# AM13E230x register map
Vendor: Texas Instruments; File version: Revised: 2025-12-26 17:30:06
CPU: CM33 r0p0, little endian, MPU, FPU, 4 interrupt priority bits
Registers are 32-bit, read-write, reset 0x0 unless marked. A register's access mark holds for its fields unless they carry their own. Offsets are from the block's base; [hi:lo] are bit positions; {n}, {i} and the like mark numbered series; 'fields as' and 'values as' point back to an identical list.

## GSC — GSC_LITE_INTERNAL_REGS
Base 0x40046000
0x1004 SPC_ATTRIBVIOLP_CONFIG — SRAM Privilege Access Attribute Violation Configuration Register
  [0] PRIVVIOL — Privilege access to non-privilege SRAM
0x1014 PPC_ATTRIBVIOLP_CONFIG — Peripheral Privilege Access Attribute Violation Configuration Register
  [0] PRIVVIOL — Privilege access to non-privilege Peripheral
0x1024 FPC_ATTRIBVIOLP_CONFIG — Flash Privilege Access Attribute Violation Configuration Register
  [0] PRIVVIOL — Privilege access to non-privilege Flash
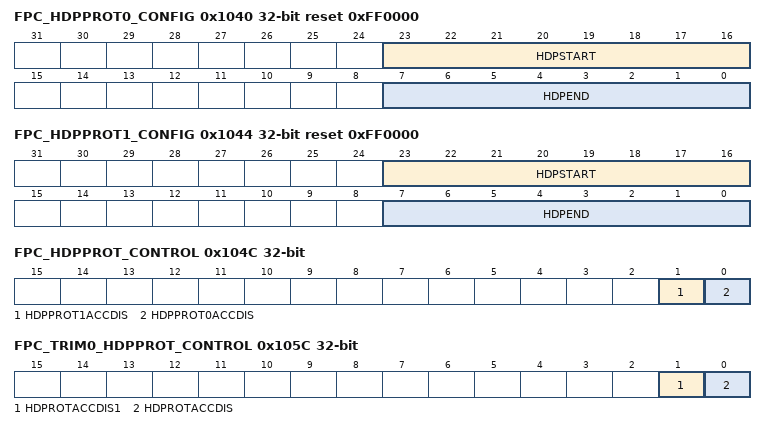
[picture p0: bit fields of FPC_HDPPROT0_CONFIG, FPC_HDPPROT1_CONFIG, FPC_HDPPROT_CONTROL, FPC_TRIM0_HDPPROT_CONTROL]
0x1040 FPC_HDPPROT0_CONFIG reset 0xFF0000 — Flash Hide Protection for Bank0 Configuration Register
  [23:16] HDPSTART wo — HDPPROT0 start sector number
  [7:0] HDPEND wo — HDPPROT0 end sector number
0x1044 FPC_HDPPROT1_CONFIG reset 0xFF0000 — Flash Hide Protection for Bank1 Configuration Register
  [23:16] HDPSTART wo — HDPPROT1 start sector number
  [7:0] HDPEND wo — HDPPROT1 end sector number
0x104C FPC_HDPPROT_CONTROL — Flash Hide Protection Control Register
  [1] HDPPROT1ACCDIS — HDP region-1 enable
  [0] HDPPROT0ACCDIS — HDP region-0 enable
0x1050 FPC_HDPEN_CONTROL — Flash Hide Protection Enable Control Register
  [0] HDPEN — HDP mode enable
0x1054 FPC_NONMAIN0_HDPPROT_CONTROL — Flash NONMAIN Bank0 Hide Protection Control Register
  [1:0] HDPROTACCDIS — HDP enable for NONMAIN region of Bank0
0x1058 FPC_NONMAIN1_HDPPROT_CONTROL — Flash NONMAIN Bank1 Hide Protection Control Register
  [1:0] HDPROTACCDIS — HDP enable for NONMAIN region of Bank1
0x105C FPC_TRIM0_HDPPROT_CONTROL — Flash TRIM Bank0 Hide Protection Control Register
  [1] HDPROTACCDIS1 — Redundant
  [0] HDPROTACCDIS — HDP enable for TRIM region of Bank0
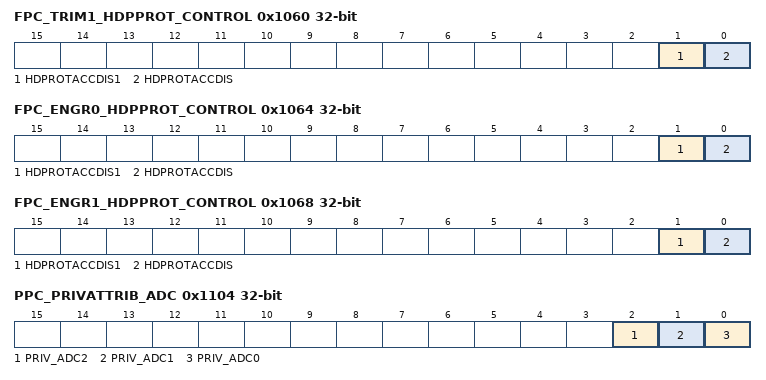
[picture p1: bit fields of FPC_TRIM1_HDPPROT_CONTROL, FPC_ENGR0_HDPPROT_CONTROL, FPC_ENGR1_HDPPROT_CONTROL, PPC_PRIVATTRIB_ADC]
0x1060 FPC_TRIM1_HDPPROT_CONTROL — Flash TRIM Bank1 Hide Protection Control Register
  [1] HDPROTACCDIS1 — Redundant
  [0] HDPROTACCDIS — HDP enable for TRIM region of Bank1
0x1064 FPC_ENGR0_HDPPROT_CONTROL — Flash ENGR Bank0 Hide Protection Control Register
  [1] HDPROTACCDIS1 — Redundant
  [0] HDPROTACCDIS — HDP enable for ENGR region of Bank0
0x1068 FPC_ENGR1_HDPPROT_CONTROL — Flash ENGR Bank1 Hide Protection Control Register
  [1] HDPROTACCDIS1 — Redundant
  [0] HDPROTACCDIS — HDP enable for ENGR region of Bank1
0x1104 PPC_PRIVATTRIB_ADC — Peripheral Privilege Access ADC
  [2] PRIV_ADC2 — Privilege access for ADC2
  [1] PRIV_ADC1 — Privilege access for ADC1
  [0] PRIV_ADC0 — Privilege access for ADC0
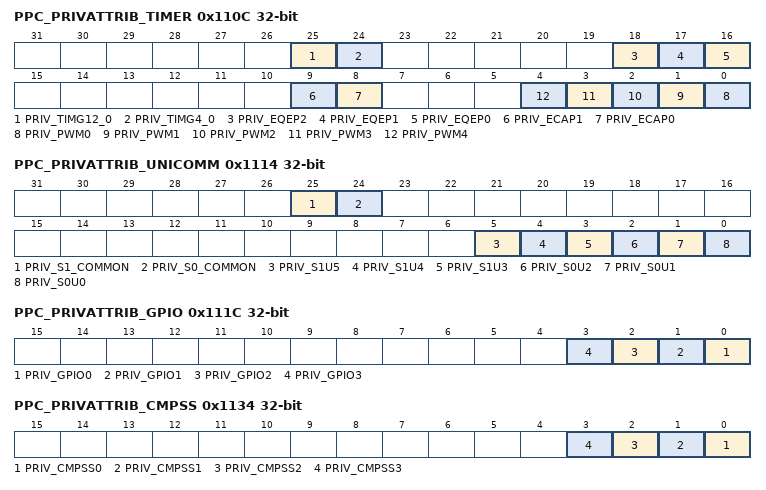
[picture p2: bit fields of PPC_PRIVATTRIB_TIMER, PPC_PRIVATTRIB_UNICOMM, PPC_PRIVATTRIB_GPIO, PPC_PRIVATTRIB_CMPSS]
0x110C PPC_PRIVATTRIB_TIMER — Peripheral Privilege Access Timer
  [25] PRIV_TIMG12_0 — Privilege access for TIMG12_0
  [24] PRIV_TIMG4_0 — Privilege access for TIMG4_0
  [18] PRIV_EQEP2 — Privilege access for EQEP2
  [17] PRIV_EQEP1 — Privilege access for EQEP1
  [16] PRIV_EQEP0 — Privilege access for EQEP0
  [9] PRIV_ECAP1 — Privilege access for ECAP1
  [8] PRIV_ECAP0 — Privilege access for ECAP0
  [n] PRIV_PWM{n} (n=0..4) — Privilege access for PWM{n}
0x1114 PPC_PRIVATTRIB_UNICOMM — Peripheral Privilege Access UniComm
  [25] PRIV_S1_COMMON — Privilege access for UniComm S1 common region
  [24] PRIV_S0_COMMON — Privilege access for UniComm S0 common region
  [5] PRIV_S1U5 — Privilege access for UniComm S1U5
  [4] PRIV_S1U4 — Privilege access for UniComm S1U4
  [3] PRIV_S1U3 — Privilege access for UniComm S1U3
  [2] PRIV_S0U2 — Privilege access for UniComm S0U2
  [1] PRIV_S0U1 — Privilege access for UniComm S0U1
  [0] PRIV_S0U0 — Privilege access for UniComm S0U0
0x111C PPC_PRIVATTRIB_GPIO — Peripheral Privilege Access GPIO
  [n] PRIV_GPIO{n} (n=0..3) — Privilege access for GPIO{n}
0x1124 PPC_PRIVATTRIB_MCAN — Peripheral Privilege Access CAN
  [0] PRIV_MCAN — Privilege access for MCAN
0x1134 PPC_PRIVATTRIB_CMPSS — Peripheral Privilege Access CMPSS
  [n] PRIV_CMPSS{n} (n=0..3) — Privilege access for CMPSS{n}
0x113C PPC_PRIVATTRIB_WDT — Peripheral Privilege Access Watchdog
  [0] PRIV_WWDT — Privilege access for Windowed Watchdog
0x114C PPC_PRIVATTRIB_CRC reset 0x1 — Peripheral Privilege Access CRC
  [0] PRIV_CRC — Privilege access for CRC
0x1154 PPC_PRIVATTRIB_AES — Peripheral Privilege Access AES
  [0] PRIV_AES — Privilege access for AES
0x116C PPC_PRIVATTRIB_IOMUX — Peripheral Privilege Access IOMUX
  [0] PRIV_IOMUX — Privilege access for IOMUX
0x1184 PPC_PRIVATTRIB_DEBUGSS reset 0x1 — Peripheral Privilege Access DEBUGSS
  [0] PRIV_DEBUGSS — Privilege access for DEBUGSS
0x1194 PPC_PRIVATTRIB_KEYSTORECTL — Peripheral Privilege Access KEYSTORECTL
  [0] PRIV_KEYSTORECTL — Privilege access for KEYSTORECTL
0x119C PPC_PRIVATTRIB_EAM — Peripheral Privilege Access EAM
  [0] PRIV_EAM — Privilege access for EAM
0x11A4 PPC_PRIVATTRIB_WUC — Peripheral Privilege Access WUC
  [0] PRIV_WUC — Privilege access for WUC
0x11AC PPC_PRIVATTRIB_FRIREGS — Peripheral Privilege Access FRIREGS
  [0] PRIV_FRIREGS — Privilege access for FRIREGS
0x11B4 PPC_PRIVATTRIB_MEMCFG — Peripheral Privilege Access MEMCFG
  [0] PRIV_MEMCFG — Privilege access for MEMCFG
0x120C PPC_PRIVATTRIB_SYSCTL reset 0x1 — Peripheral Privilege Access System Control
  [0] PRIV_SYSCTL — Privilege access for SYSCTL
0x1214 PPC_PRIVATTRIB_DMA reset 0x1 — Peripheral Privilege Access DMA
  [0] PRIV_DMA — Privilege access for DMA
0x121C PPC_PRIVATTRIB_GSC reset 0x1 — Peripheral Privilege Access GSC
  [0] PRIV_GSC — Privilege access for GSC
0x1224 PPC_PRIVATTRIB_COPROC — Peripheral Privilege Access Co-processor
  [0] PRIV_TINIE — Privilege access for TINIE
0x122C PPC_PRIVATTRIB_EPI — Peripheral Privilege Access EPI
  [0] PRIV_EPI — Privilege access for EPI
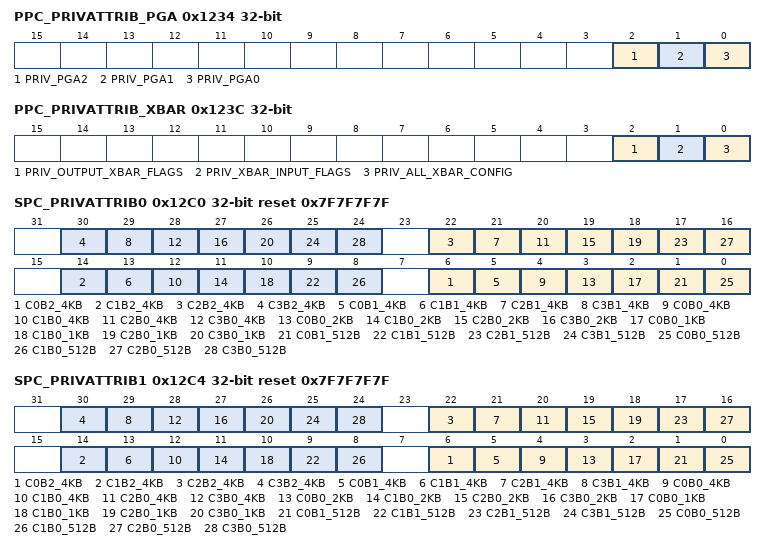
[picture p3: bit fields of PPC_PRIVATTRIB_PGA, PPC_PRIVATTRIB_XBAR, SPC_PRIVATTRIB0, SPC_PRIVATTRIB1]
0x1234 PPC_PRIVATTRIB_PGA — Peripheral Privilege Access PGA
  [2] PRIV_PGA2 — Privilege access for PGA2
  [1] PRIV_PGA1 — Privilege access for PGA1
  [0] PRIV_PGA0 — Privilege access for PGA0
0x123C PPC_PRIVATTRIB_XBAR — Peripheral Privilege Access XBAR
  [2] PRIV_OUTPUT_XBAR_FLAGS — Privilege access for OUTPUT_XBAR_FLAGS
  [1] PRIV_XBAR_INPUT_FLAGS — Privilege access for XBAR_INPUT_FLAGS
  [0] PRIV_ALL_XBAR_CONFIG — Privilege access for ALL_XBAR_CONFIG
0x12C0 SPC_PRIVATTRIB0 reset 0x7F7F7F7F — SRAM Privilege Attribute-0 Register
  [8n+6] C{n}B2_4KB (n=0..3) — privilege access for third 4KB in chunk {n}
  [8n+5] C{n}B1_4KB (n=0..3) — privilege access for second 4KB in chunk {n}
  [8n+4] C{n}B0_4KB (n=0..3) — privilege access for first 4KB in chunk {n}
  [8n+3] C{n}B0_2KB (n=0..3) — privilege access for 2KB in chunk {n}
  [8n+2] C{n}B0_1KB (n=0..3) — privilege access for 1KB in chunk {n}
  [8n+1] C{n}B1_512B (n=0..3) — privilege access for second 512 byte in chunk {n}
  [8n] C{n}B0_512B (n=0..3) — privilege access for first 512 byte in chunk {n}
0x12C4 SPC_PRIVATTRIB1 reset 0x7F7F7F7F — SRAM Privilege Attribute-1 Register
  fields as SPC_PRIVATTRIB0
0x1400 FPC_PRIVATTRIBA0 reset 0xFFFFFFFF — Flash Privilege Attribute Register A0
0x1404 FPC_PRIVATTRIBA1 reset 0xFFFFFFFF — Flash Privilege Attribute Register A1
0x1408 FPC_PRIVATTRIBB0 reset 0xFFF0 — Flash Privilege Attribute Register B0
  [15:4] PRIV_PAGE — Privilege access for higher sectors of Bank0
0x140C FPC_PRIVATTRIBB1 reset 0xFFF0 — Flash Privilege Attribute Register B1
  [15:4] PRIV_PAGE — Privilege access for higher sectors of Bank1
0x1410 FPC_NONMAIN_PRIVATTRIB0 reset 0x3 — Flash Non-Main Privilege Attribute Register B0
  [1:0] PRIV_PAGE — Privilege access for Nonmain region of Bank0
0x1414 FPC_NONMAIN_PRIVATTRIB1 reset 0x3 — Flash Non-Main Privilege Attribute Register B1
  [1:0] PRIV_PAGE — Privilege access for Nonmain region of Bank1
0x1418 FPC_TRIM_PRIVATTRIB0 reset 0x1 — Flash Trim Privilege Attribute Register B0
  [0] PRIV_PAGE — Privilege access for TRIM region of Bank0
0x141C FPC_TRIM_PRIVATTRIB1 reset 0x1 — Flash Trim Privilege Attribute Register B1
  [0] PRIV_PAGE — Privilege access for TRIM region of Bank1
0x1420 FPC_ENGR_PRIVATTRIB0 reset 0x1 — Flash Engr Privilege Attribute Register B0
  [0] PRIV_PAGE — Privilege access for ENGR region of Bank0
0x1424 FPC_ENGR_PRIVATTRIB1 reset 0x1 — Flash Engr Privilege Attribute Register B1
  [0] PRIV_PAGE — Privilege access for ENGR region of Bank1
0x1600 FPC_WEPROTA0 — Flash Write Protect Attribute Register A0
0x1604 FPC_WEPROTA1 — Flash Write Protect Attribute Register A1
0x1608 FPC_WEPROTB0 — Flash Write Protect Attribute Register B0
  [15:4] WEPROT_PAGE — Erase/program protection for higher sectors of Flash Bank0
0x160C FPC_WEPROTB1 — Flash Write Protect Attribute Register B1
  [15:4] WEPROT_PAGE — Erase/program protection for higher sectors of Flash Bank1
0x1610 FPC_WEPROTNONMAIN0 — Flash Non-Main Write Protect Attribute Register B0
  [1:0] WEPROT_PAGE — Erase/program protection for Flash NONMAIN region of Bank0
0x1614 FPC_WEPROTNONMAIN1 — Flash Non-Main Write Protect Attribute Register B1
  [1:0] WEPROT_PAGE — Erase/program protection for Flash NONMAIN region of Bank1
0x1618 FPC_WEPROTTRIM0 — Flash Trim Write Protect Attribute Register B0
  [1:0] WEPROT_PAGE — Erase/program protection for Flash TRIM region of Bank0
0x161C FPC_WEPROTTRIM1 — Flash Trim Write Protect Attribute Register B1
  [1:0] WEPROT_PAGE — Erase/program protection for Flash TRIM region of Bank1
0x1620 FPC_WEPROTENGR0 — Flash Engr Write Protect Attribute Register B0
  [1:0] WEPROT_PAGE — Erase/program protection for Flash ENGR region of Bank0
0x1624 FPC_WEPROTENGR1 — Flash Engr Write Protect Attribute Register B1
  [1:0] WEPROT_PAGE — Erase/program protection for Flash ENGR region of Bank1
0x1800 FPC_FLSEMREQ — Flash semaphore request register
  [0] REQ — Request Semaphore Ownership
0x1804 FPC_FLSEMCLR — Flash semaphore release register
  [0] CLR — Release Semaphore Ownership
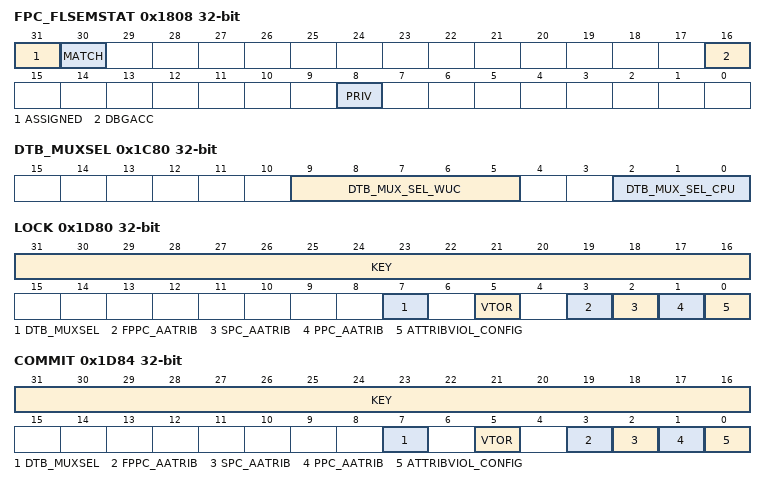
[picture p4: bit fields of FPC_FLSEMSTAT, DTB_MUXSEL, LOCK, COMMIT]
0x1808 FPC_FLSEMSTAT — Flash semaphore statys registers
  [31] ASSIGNED ro — Assigned Flag
  [30] MATCH ro — Match Status Bit
  [16] DBGACC ro — Semaphore debug access
  [8] PRIV ro — Semaphore Privilage attribute
0x1B84 VTOR_NS reset 0x1000001 — Non - Secure Vector Table Offset Register
0x1C80 DTB_MUXSEL — Digital Test Bus MUX Selection
  [9:5] DTB_MUX_SEL_WUC — WUC DTB MUX sel
  [2:0] DTB_MUX_SEL_CPU — CPU DTB MUX sel
0x1D80 LOCK — GSC Lock configuration register
  [31:16] KEY wo — Write key: the write only takes effect if KEY is 0xA551
    0xA551=UNLOCK (Write 0xA551 to update the register)
  [7] DTB_MUXSEL — Register lock configuration
  [5] VTOR — Register lock configuration
  [3] FPPC_AATRIB — Register lock configuration
  [2] SPC_AATRIB — Register lock configuration
  [1] PPC_AATRIB — Register lock configuration
  [0] ATTRIBVIOL_CONFIG — Register lock configuration
0x1D84 COMMIT — GSC commit configuration register
  [31:16] KEY wo — Write key: the write only takes effect if KEY is 0xA442
    0xA442=UNLOCK (Write 0xA442 to update the register)
  [7] DTB_MUXSEL — Register lock committed
  [5] VTOR — Register lock committed
  [3] FPPC_AATRIB — Register lock committed
  [2] SPC_AATRIB — Register lock committed
  [1] PPC_AATRIB — Register lock committed
  [0] ATTRIBVIOL_CONFIG — Register lock committed
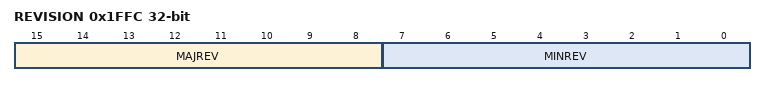
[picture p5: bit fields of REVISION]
0x1FFC REVISION — GSC Revision register
  [15:8] MAJREV ro — Major Revision Number
  [7:0] MINREV ro — Minor Revision Number
